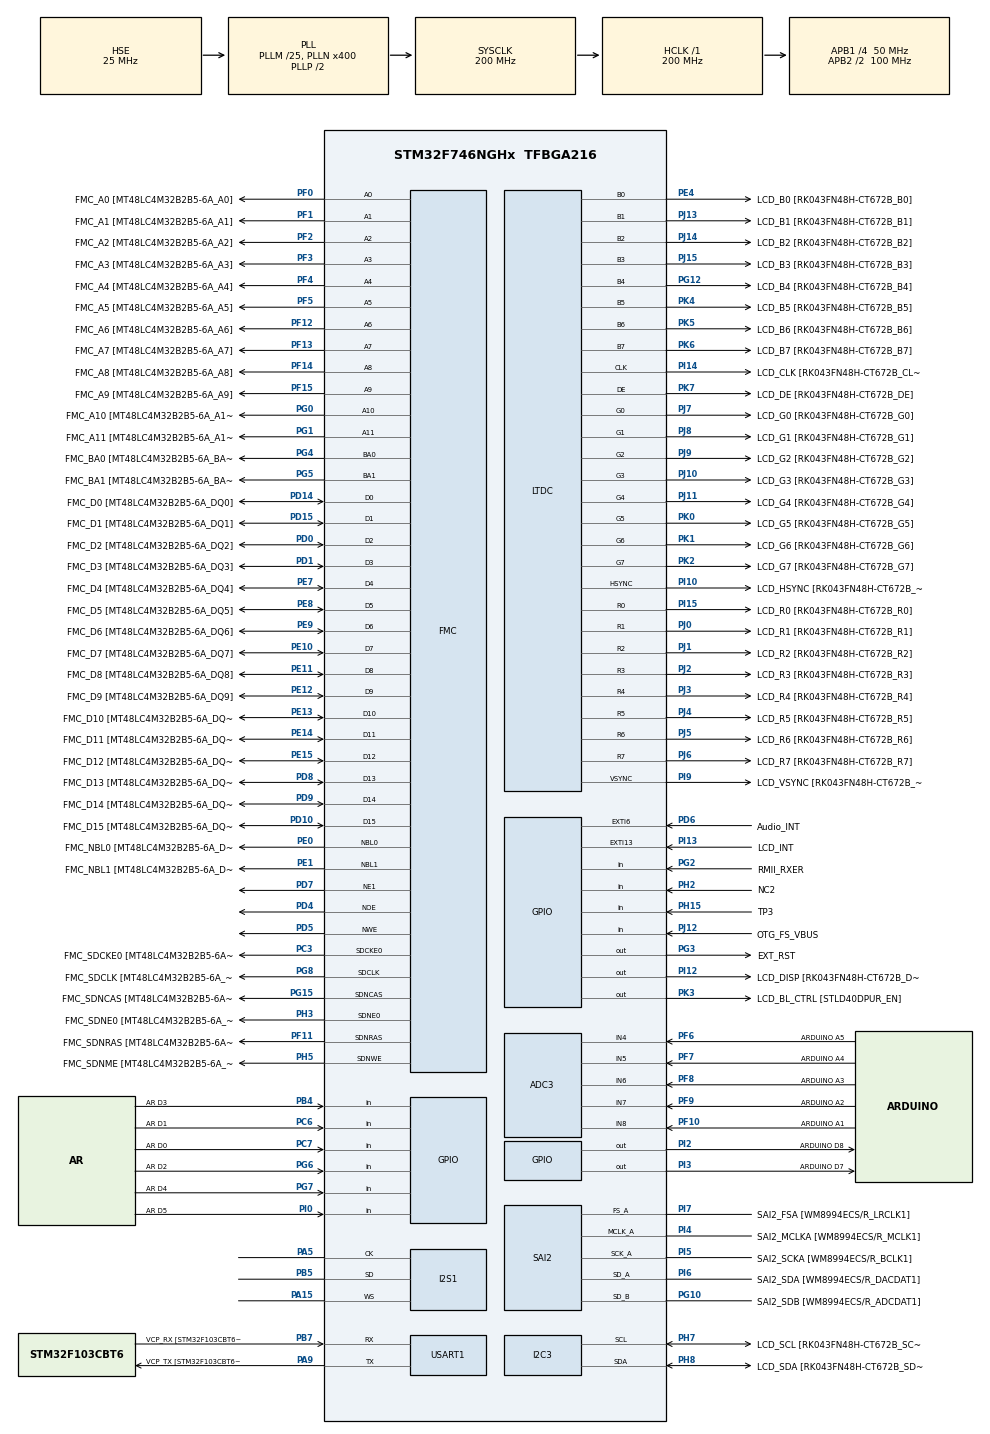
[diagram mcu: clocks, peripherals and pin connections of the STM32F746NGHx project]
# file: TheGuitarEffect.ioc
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ADC3.Channel-0\#ChannelRegularConversion=ADC_CHANNEL_4
ADC3.Channel-IN4=ADC_CHANNEL_4
ADC3.Channel-IN5=ADC_CHANNEL_5
ADC3.Channel-IN6=ADC_CHANNEL_6
ADC3.Channel-IN7=ADC_CHANNEL_7
ADC3.Channel-IN8=ADC_CHANNEL_8
ADC3.ContinuousConvMode=ENABLE
ADC3.EOCSelection=ADC_EOC_SEQ_CONV
CORTEX_M7.AccessPermission-Cortex_Memory_Protection_Unit_Region1_Settings=MPU_REGION_FULL_ACCESS
CORTEX_M7.AccessPermission-Cortex_Memory_Protection_Unit_Region2_Settings=MPU_REGION_FULL_ACCESS
CORTEX_M7.AccessPermission-Cortex_Memory_Protection_Unit_Region3_Settings=MPU_REGION_FULL_ACCESS
CORTEX_M7.BaseAddress-Cortex_Memory_Protection_Unit_Region0_Settings=0x00
CORTEX_M7.BaseAddress-Cortex_Memory_Protection_Unit_Region1_Settings=0xC0000000
CORTEX_M7.BaseAddress-Cortex_Memory_Protection_Unit_Region2_Settings=0x90000000
CORTEX_M7.BaseAddress-Cortex_Memory_Protection_Unit_Region3_Settings=0xA0000000
CORTEX_M7.CPU_DCache=Enabled
CORTEX_M7.CPU_ICache=Enabled
CORTEX_M7.DisableExec-Cortex_Memory_Protection_Unit_Region0_Settings=MPU_INSTRUCTION_ACCESS_DISABLE
CORTEX_M7.DisableExec-Cortex_Memory_Protection_Unit_Region3_Settings=MPU_INSTRUCTION_ACCESS_DISABLE
CORTEX_M7.Enable-Cortex_Memory_Protection_Unit_Region0_Settings=MPU_REGION_ENABLE
CORTEX_M7.Enable-Cortex_Memory_Protection_Unit_Region1_Settings=MPU_REGION_ENABLE
CORTEX_M7.Enable-Cortex_Memory_Protection_Unit_Region2_Settings=MPU_REGION_ENABLE
CORTEX_M7.Enable-Cortex_Memory_Protection_Unit_Region3_Settings=MPU_REGION_ENABLE
CORTEX_M7.IsBufferable-Cortex_Memory_Protection_Unit_Region3_Settings=MPU_ACCESS_BUFFERABLE
CORTEX_M7.IsCacheable-Cortex_Memory_Protection_Unit_Region1_Settings=MPU_ACCESS_CACHEABLE
CORTEX_M7.IsCacheable-Cortex_Memory_Protection_Unit_Region2_Settings=MPU_ACCESS_CACHEABLE
CORTEX_M7.IsShareable-Cortex_Memory_Protection_Unit_Region0_Settings=MPU_ACCESS_SHAREABLE
CORTEX_M7.IsShareable-Cortex_Memory_Protection_Unit_Region3_Settings=MPU_ACCESS_SHAREABLE
CORTEX_M7.MPU_Control=MPU_PRIVILEGED_DEFAULT
CORTEX_M7.Size-Cortex_Memory_Protection_Unit_Region0_Settings=MPU_REGION_SIZE_4GB
CORTEX_M7.Size-Cortex_Memory_Protection_Unit_Region1_Settings=MPU_REGION_SIZE_32MB
CORTEX_M7.Size-Cortex_Memory_Protection_Unit_Region2_Settings=MPU_REGION_SIZE_64MB
CORTEX_M7.Size-Cortex_Memory_Protection_Unit_Region3_Settings=MPU_REGION_SIZE_8KB
CORTEX_M7.SubRegionDisable-Cortex_Memory_Protection_Unit_Region0_Settings=0x87
CORTEX_M7.SubRegionDisable-Cortex_Memory_Protection_Unit_Region1_Settings=0x00
Dma.ADC3.0.Direction=DMA_PERIPH_TO_MEMORY
Dma.ADC3.0.FIFOMode=DMA_FIFOMODE_DISABLE
Dma.ADC3.0.Instance=DMA2_Stream1
Dma.ADC3.0.MemDataAlignment=DMA_MDATAALIGN_HALFWORD
Dma.ADC3.0.MemInc=DMA_MINC_ENABLE
Dma.ADC3.0.Mode=DMA_NORMAL
Dma.ADC3.0.PeriphDataAlignment=DMA_PDATAALIGN_HALFWORD
Dma.ADC3.0.PeriphInc=DMA_PINC_DISABLE
Dma.ADC3.0.Priority=DMA_PRIORITY_MEDIUM
Dma.Request0=ADC3
FMC.CASLatency1=FMC_SDRAM_CAS_LATENCY_3
FMC.ExitSelfRefreshDelay1=7
FMC.LoadToActiveDelay1=2
FMC.RCDDelay1=2
FMC.RPDelay1=2
FMC.ReadBurst1=FMC_SDRAM_RBURST_ENABLE
FMC.RowCycleDelay1=7
FMC.SDClockPeriod1=FMC_SDRAM_CLOCK_PERIOD_2
FMC.SelfRefreshTime1=4
FMC.WriteRecoveryTime1=3
I2C3.Timing=0x00C0EAFF
I2S1.ErrorAudioFreq=0.15 %
I2S1.FullDuplexMode=I2S_FULLDUPLEXMODE_DISABLE
I2S1.Instance=SPI$Index
I2S1.RealAudioFreq=8.012 KHz
I2S1.VirtualMode=I2S_MODE_MASTER
LTDC.ActiveH=272
LTDC.ActiveW=480
LTDC.Alpha_L0=255
LTDC.BlendingFactor1_L0=LTDC_BLENDING_FACTOR1_PAxCA
LTDC.BlendingFactor2_L0=LTDC_BLENDING_FACTOR2_PAxCA
LTDC.FBStartAdress_L0=0xC0000000
LTDC.HBP=13
LTDC.HFP=32
LTDC.HSync=41
LTDC.ImageHeight_L0=272
LTDC.ImageWidth_L0=480
LTDC.Layers=0
LTDC.PixelFormat_L0=LTDC_PIXEL_FORMAT_RGB565
LTDC.VSync=10
LTDC.WindowX1_L0=480
LTDC.WindowY1_L0=272
Mcu.Family=STM32F7
Mcu.Name=STM32F746NGHx
Mcu.Package=TFBGA216
NVIC.ADC_IRQn=true\:0\:0\:false\:false\:true\:true\:true\:true
NVIC.DMA2D_IRQn=true\:0\:0\:false\:false\:true\:true\:true\:true
NVIC.DMA2_Stream1_IRQn=true\:0\:0\:false\:false\:true\:false\:true\:true
NVIC.FMC_IRQn=true\:0\:0\:false\:false\:true\:true\:true\:true
NVIC.LTDC_IRQn=true\:0\:0\:false\:false\:true\:true\:true\:true
NVIC.PriorityGroup=NVIC_PRIORITYGROUP_4
NVIC.TIM6_DAC_IRQn=true\:15\:0\:false\:false\:true\:false\:true\:true
NVIC.TimeBase=TIM6_DAC_IRQn
NVIC.TimeBaseIP=TIM6
PA13.GPIO_Label=SWDIO
PA13.Mode=Serial_Wire
PA13.Signal=SYS_JTMS-SWDIO
PA14.GPIO_Label=SWCLK
PA14.Mode=Serial_Wire
PA14.Signal=SYS_JTCK-SWCLK
PA15.Mode=Half_Duplex_Master
PA15.Signal=I2S1_WS
PA5.Mode=Half_Duplex_Master
PA5.Signal=I2S1_CK
PA9.GPIO_Label=VCP_TX [STM32F103CBT6_PA3]
PA9.GPIO_Mode=GPIO_MODE_AF_PP
PA9.GPIO_PuPd=GPIO_NOPULL
PA9.GPIO_Speed=GPIO_SPEED_FREQ_LOW
PA9.Mode=Asynchronous
PA9.Signal=USART1_TX
PB3.GPIO_Label=SWO
PB3.Signal=SYS_JTDO-SWO
PB4.GPIO_Label=AR D3
PB4.Signal=GPIO_Input
PB5.Mode=Half_Duplex_Master
PB5.Signal=I2S1_SD
PB7.GPIO_Label=VCP_RX [STM32F103CBT6_PA2]
PB7.GPIO_Mode=GPIO_MODE_AF_PP
PB7.GPIO_PuPd=GPIO_NOPULL
PB7.GPIO_Speed=GPIO_SPEED_FREQ_LOW
PB7.Mode=Asynchronous
PB7.Signal=USART1_RX
PC14/OSC32_IN.GPIO_Label=RCC_OSC32_IN
PC14/OSC32_IN.Signal=RCC_OSC32_IN
PC15/OSC32_OUT.GPIO_Label=RCC_OSC32_OUT
PC15/OSC32_OUT.Signal=RCC_OSC32_OUT
PC3.GPIO_Label=FMC_SDCKE0 [MT48LC4M32B2B5-6A_CKE]
PC3.Mode=SdramChipSelect1_1
PC3.Signal=FMC_SDCKE0
PC6.GPIO_Label=AR D1
PC6.Signal=GPIO_Input
PC7.GPIO_Label=AR D0
PC7.Signal=GPIO_Input
PD0.GPIO_Label=FMC_D2 [MT48LC4M32B2B5-6A_DQ2]
PD0.Signal=FMC_D2_DA2
PD1.GPIO_Label=FMC_D3 [MT48LC4M32B2B5-6A_DQ3]
PD1.Signal=FMC_D3_DA3
PD10.GPIO_Label=FMC_D15 [MT48LC4M32B2B5-6A_DQ15]
PD10.Signal=FMC_D15_DA15
PD14.GPIO_Label=FMC_D0 [MT48LC4M32B2B5-6A_DQ0]
PD14.Signal=FMC_D0_DA0
PD15.GPIO_Label=FMC_D1 [MT48LC4M32B2B5-6A_DQ1]
PD15.Signal=FMC_D1_DA1
PD4.Signal=FMC_NOE
PD5.Signal=FMC_NWE
PD6.GPIO_Label=Audio_INT
PD6.GPIO_ModeDefaultEXTI=GPIO_MODE_EVT_RISING
PD6.Signal=GPXTI6
PD7.Mode=NorPsramChipSelect1_1
PD7.Signal=FMC_NE1
PD8.GPIO_Label=FMC_D13 [MT48LC4M32B2B5-6A_DQ13]
PD8.Signal=FMC_D13_DA13
PD9.GPIO_Label=FMC_D14 [MT48LC4M32B2B5-6A_DQ14]
PD9.Signal=FMC_D14_DA14
PE0.GPIO_Label=FMC_NBL0 [MT48LC4M32B2B5-6A_DQM0]
PE0.Signal=FMC_NBL0
PE1.GPIO_Label=FMC_NBL1 [MT48LC4M32B2B5-6A_DQM1]
PE1.Signal=FMC_NBL1
PE10.GPIO_Label=FMC_D7 [MT48LC4M32B2B5-6A_DQ7]
PE10.Signal=FMC_D7_DA7
PE11.GPIO_Label=FMC_D8 [MT48LC4M32B2B5-6A_DQ8]
PE11.Signal=FMC_D8_DA8
PE12.GPIO_Label=FMC_D9 [MT48LC4M32B2B5-6A_DQ9]
PE12.Signal=FMC_D9_DA9
PE13.GPIO_Label=FMC_D10 [MT48LC4M32B2B5-6A_DQ10]
PE13.Signal=FMC_D10_DA10
PE14.GPIO_Label=FMC_D11 [MT48LC4M32B2B5-6A_DQ11]
PE14.Signal=FMC_D11_DA11
PE15.GPIO_Label=FMC_D12 [MT48LC4M32B2B5-6A_DQ12]
PE15.Signal=FMC_D12_DA12
PE4.GPIO_Label=LCD_B0 [RK043FN48H-CT672B_B0]
PE4.Mode=RGB888
PE4.Signal=LTDC_B0
PE7.GPIO_Label=FMC_D4 [MT48LC4M32B2B5-6A_DQ4]
PE7.Signal=FMC_D4_DA4
PE8.GPIO_Label=FMC_D5 [MT48LC4M32B2B5-6A_DQ5]
PE8.Signal=FMC_D5_DA5
PE9.GPIO_Label=FMC_D6 [MT48LC4M32B2B5-6A_DQ6]
PE9.Signal=FMC_D6_DA6
PF0.GPIO_Label=FMC_A0 [MT48LC4M32B2B5-6A_A0]
PF0.Signal=FMC_A0
PF1.GPIO_Label=FMC_A1 [MT48LC4M32B2B5-6A_A1]
PF1.Signal=FMC_A1
PF10.GPIO_Label=ARDUINO A1
PF10.GPIO_Mode=GPIO_MODE_ANALOG
PF10.GPIO_PuPd=GPIO_NOPULL
PF10.Mode=IN8
PF10.Signal=ADC3_IN8
PF11.GPIO_Label=FMC_SDNRAS [MT48LC4M32B2B5-6A_RAS]
PF11.Signal=FMC_SDNRAS
PF12.GPIO_Label=FMC_A6 [MT48LC4M32B2B5-6A_A6]
PF12.Signal=FMC_A6
PF13.GPIO_Label=FMC_A7 [MT48LC4M32B2B5-6A_A7]
PF13.Signal=FMC_A7
PF14.GPIO_Label=FMC_A8 [MT48LC4M32B2B5-6A_A8]
PF14.Signal=FMC_A8
PF15.GPIO_Label=FMC_A9 [MT48LC4M32B2B5-6A_A9]
PF15.Signal=FMC_A9
PF2.GPIO_Label=FMC_A2 [MT48LC4M32B2B5-6A_A2]
PF2.Signal=FMC_A2
PF3.GPIO_Label=FMC_A3 [MT48LC4M32B2B5-6A_A3]
PF3.Signal=FMC_A3
PF4.GPIO_Label=FMC_A4 [MT48LC4M32B2B5-6A_A4]
PF4.Signal=FMC_A4
PF5.GPIO_Label=FMC_A5 [MT48LC4M32B2B5-6A_A5]
PF5.Signal=FMC_A5
PF6.GPIO_Label=ARDUINO A5
PF6.GPIO_Mode=GPIO_MODE_ANALOG
PF6.GPIO_PuPd=GPIO_NOPULL
PF6.Mode=IN4
PF6.Signal=ADC3_IN4
PF7.GPIO_Label=ARDUINO A4
PF7.GPIO_Mode=GPIO_MODE_ANALOG
PF7.GPIO_PuPd=GPIO_NOPULL
PF7.Mode=IN5
PF7.Signal=ADC3_IN5
PF8.GPIO_Label=ARDUINO A3
PF8.GPIO_Mode=GPIO_MODE_ANALOG
PF8.GPIO_PuPd=GPIO_NOPULL
PF8.Mode=IN6
PF8.Signal=ADC3_IN6
PF9.GPIO_Label=ARDUINO A2
PF9.GPIO_Mode=GPIO_MODE_ANALOG
PF9.GPIO_PuPd=GPIO_NOPULL
PF9.Mode=IN7
PF9.Signal=ADC3_IN7
PG0.GPIO_Label=FMC_A10 [MT48LC4M32B2B5-6A_A10]
PG0.Signal=FMC_A10
PG1.GPIO_Label=FMC_A11 [MT48LC4M32B2B5-6A_A11]
PG1.Signal=FMC_A11
PG10.GPIO_Label=SAI2_SDB [WM8994ECS/R_ADCDAT1]
PG10.GPIO_Speed=GPIO_SPEED_FREQ_MEDIUM
PG10.Mode=SAI_B_SyncSlave
PG10.Signal=SAI2_SD_B
PG12.GPIO_Label=LCD_B4 [RK043FN48H-CT672B_B4]
PG12.Mode=RGB888
PG12.Signal=LTDC_B4
PG15.GPIO_Label=FMC_SDNCAS [MT48LC4M32B2B5-6A_CAS]
PG15.Signal=FMC_SDNCAS
PG2.GPIO_Label=RMII_RXER
PG2.Signal=GPIO_Input
PG3.GPIO_Label=EXT_RST
PG3.Signal=GPIO_Output
PG4.GPIO_Label=FMC_BA0 [MT48LC4M32B2B5-6A_BA0]
PG4.Signal=FMC_A14_BA0
PG5.GPIO_Label=FMC_BA1 [MT48LC4M32B2B5-6A_BA1]
PG5.Signal=FMC_A15_BA1
PG6.GPIO_Label=AR D2
PG6.Signal=GPIO_Input
PG7.GPIO_Label=AR D4
PG7.Signal=GPIO_Input
PG8.GPIO_Label=FMC_SDCLK [MT48LC4M32B2B5-6A_CLK]
PG8.Signal=FMC_SDCLK
PH0/OSC_IN.GPIO_Label=OSC_25M [NZ2520SB-25.00M_OUT]
PH0/OSC_IN.Mode=HSE-External-Oscillator
PH0/OSC_IN.Signal=RCC_OSC_IN
PH1/OSC_OUT.Mode=HSE-External-Oscillator
PH1/OSC_OUT.Signal=RCC_OSC_OUT
PH15.GPIO_Label=TP3
PH15.Signal=GPIO_Input
PH2.GPIO_Label=NC2
PH2.Signal=GPIO_Input
PH3.GPIO_Label=FMC_SDNE0 [MT48LC4M32B2B5-6A_CS]
PH3.Mode=SdramChipSelect1_1
PH3.Signal=FMC_SDNE0
PH5.GPIO_Label=FMC_SDNME [MT48LC4M32B2B5-6A_WE]
PH5.Signal=FMC_SDNWE
PH7.GPIO_Label=LCD_SCL [RK043FN48H-CT672B_SCL]
PH7.GPIO_Pu=GPIO_PULLUP
PH7.Mode=I2C
PH7.Signal=I2C3_SCL
PH8.GPIO_Label=LCD_SDA [RK043FN48H-CT672B_SDA]
PH8.GPIO_Pu=GPIO_PULLUP
PH8.Mode=I2C
PH8.Signal=I2C3_SDA
PI0.GPIO_Label=AR D5
PI0.Signal=GPIO_Input
PI10.GPIO_Label=LCD_HSYNC [RK043FN48H-CT672B_HSYNC]
PI10.Mode=RGB888
PI10.Signal=LTDC_HSYNC
PI12.GPIO_Label=LCD_DISP [RK043FN48H-CT672B_DISP] 
PI12.PinState=GPIO_PIN_SET
PI12.Signal=GPIO_Output
PI13.GPIO_Label=LCD_INT
PI13.GPIO_ModeDefaultEXTI=GPIO_MODE_EVT_RISING
PI13.Signal=GPXTI13
PI14.GPIO_Label=LCD_CLK [RK043FN48H-CT672B_CLK]
PI14.Mode=RGB888
PI14.Signal=LTDC_CLK
PI15.GPIO_Label=LCD_R0 [RK043FN48H-CT672B_R0]
PI15.Mode=RGB888
PI15.Signal=LTDC_R0
PI2.GPIO_Label=ARDUINO D8
PI2.Signal=GPIO_Output
PI3.GPIO_Label=ARDUINO D7
PI3.Signal=GPIO_Output
PI4.GPIO_Label=SAI2_MCLKA [WM8994ECS/R_MCLK1]
PI4.GPIO_Speed=GPIO_SPEED_FREQ_MEDIUM
PI4.Mode=SAI_A_MasterWithClock
PI4.Signal=SAI2_MCLK_A
PI5.GPIO_Label=SAI2_SCKA [WM8994ECS/R_BCLK1]
PI5.GPIO_Speed=GPIO_SPEED_FREQ_MEDIUM
PI5.Mode=SAI_A_MasterWithClock
PI5.Signal=SAI2_SCK_A
PI6.GPIO_Label=SAI2_SDA [WM8994ECS/R_DACDAT1]
PI6.GPIO_Speed=GPIO_SPEED_FREQ_MEDIUM
PI6.Mode=SAI_A_MasterWithClock
PI6.Signal=SAI2_SD_A
PI7.GPIO_Label=SAI2_FSA [WM8994ECS/R_LRCLK1]
PI7.GPIO_Speed=GPIO_SPEED_FREQ_MEDIUM
PI7.Mode=SAI_A_MasterWithClock
PI7.Signal=SAI2_FS_A
PI8.GPIO_Label=NC1 [TP2]
PI8.Signal=RTC_TS
PI9.GPIO_Label=LCD_VSYNC [RK043FN48H-CT672B_VSYNC]
PI9.Mode=RGB888
PI9.Signal=LTDC_VSYNC
PJ0.GPIO_Label=LCD_R1 [RK043FN48H-CT672B_R1]
PJ0.Mode=RGB888
PJ0.Signal=LTDC_R1
PJ1.GPIO_Label=LCD_R2 [RK043FN48H-CT672B_R2]
PJ1.Mode=RGB888
PJ1.Signal=LTDC_R2
PJ10.GPIO_Label=LCD_G3 [RK043FN48H-CT672B_G3]
PJ10.Mode=RGB888
PJ10.Signal=LTDC_G3
PJ11.GPIO_Label=LCD_G4 [RK043FN48H-CT672B_G4]
PJ11.Mode=RGB888
PJ11.Signal=LTDC_G4
PJ12.GPIO_Label=OTG_FS_VBUS
PJ12.Signal=GPIO_Input
PJ13.GPIO_Label=LCD_B1 [RK043FN48H-CT672B_B1]
PJ13.Mode=RGB888
PJ13.Signal=LTDC_B1
PJ14.GPIO_Label=LCD_B2 [RK043FN48H-CT672B_B2]
PJ14.Mode=RGB888
PJ14.Signal=LTDC_B2
PJ15.GPIO_Label=LCD_B3 [RK043FN48H-CT672B_B3]
PJ15.Mode=RGB888
PJ15.Signal=LTDC_B3
PJ2.GPIO_Label=LCD_R3 [RK043FN48H-CT672B_R3]
PJ2.Mode=RGB888
PJ2.Signal=LTDC_R3
PJ3.GPIO_Label=LCD_R4 [RK043FN48H-CT672B_R4]
PJ3.Mode=RGB888
PJ3.Signal=LTDC_R4
PJ4.GPIO_Label=LCD_R5 [RK043FN48H-CT672B_R5]
PJ4.Mode=RGB888
PJ4.Signal=LTDC_R5
PJ5.GPIO_Label=LCD_R6 [RK043FN48H-CT672B_R6]
PJ5.Mode=RGB888
PJ5.Signal=LTDC_R6
PJ6.GPIO_Label=LCD_R7 [RK043FN48H-CT672B_R7]
PJ6.Mode=RGB888
PJ6.Signal=LTDC_R7
PJ7.GPIO_Label=LCD_G0 [RK043FN48H-CT672B_G0]
PJ7.Mode=RGB888
PJ7.Signal=LTDC_G0
PJ8.GPIO_Label=LCD_G1 [RK043FN48H-CT672B_G1]
PJ8.Mode=RGB888
PJ8.Signal=LTDC_G1
PJ9.GPIO_Label=LCD_G2 [RK043FN48H-CT672B_G2]
PJ9.Mode=RGB888
PJ9.Signal=LTDC_G2
PK0.GPIO_Label=LCD_G5 [RK043FN48H-CT672B_G5]
PK0.Mode=RGB888
PK0.Signal=LTDC_G5
PK1.GPIO_Label=LCD_G6 [RK043FN48H-CT672B_G6]
PK1.Mode=RGB888
PK1.Signal=LTDC_G6
PK2.GPIO_Label=LCD_G7 [RK043FN48H-CT672B_G7]
PK2.Mode=RGB888
PK2.Signal=LTDC_G7
PK3.GPIO_Label=LCD_BL_CTRL [STLD40DPUR_EN]
PK3.GPIO_Speed=GPIO_SPEED_FREQ_LOW
PK3.PinState=GPIO_PIN_SET
PK3.Signal=GPIO_Output
PK4.GPIO_Label=LCD_B5 [RK043FN48H-CT672B_B5]
PK4.Mode=RGB888
PK4.Signal=LTDC_B5
PK5.GPIO_Label=LCD_B6 [RK043FN48H-CT672B_B6]
PK5.Mode=RGB888
PK5.Signal=LTDC_B6
PK6.GPIO_Label=LCD_B7 [RK043FN48H-CT672B_B7]
PK6.Mode=RGB888
PK6.Signal=LTDC_B7
PK7.GPIO_Label=LCD_DE [RK043FN48H-CT672B_DE]
PK7.Mode=RGB888
PK7.Signal=LTDC_DE
ProjectManager.HeapSize=0x200
ProjectManager.StackSize=0x400
ProjectManager.TargetToolchain=STM32CubeIDE
RCC.AHBFreq_Value=200000000
RCC.APB1CLKDivider=RCC_HCLK_DIV4
RCC.APB1Freq_Value=50000000
RCC.APB1TimFreq_Value=100000000
RCC.APB2CLKDivider=RCC_HCLK_DIV2
RCC.APB2Freq_Value=100000000
RCC.APB2TimFreq_Value=200000000
RCC.CortexFreq_Value=200000000
RCC.HCLKFreq_Value=200000000
RCC.HSE_VALUE=25000000
RCC.HSI_VALUE=16000000
RCC.LSE_VALUE=32768
RCC.PLL48CLockSelection=RCC_CLK48SOURCE_PLLSAIP
RCC.PLLI2SN=100
RCC.PLLM=25
RCC.PLLN=400
RCC.PLLQ=9
RCC.PLLSAIN=384
RCC.PLLSAIP=RCC_PLLSAIP_DIV8
RCC.PLLSAIR=5
RCC.PLLSAIRDiv=RCC_PLLSAIDIVR_8
RCC.PLLSourceVirtual=RCC_PLLSOURCE_HSE
RCC.SDMMCClockSelection=RCC_SDMMC1CLKSOURCE_CLK48
RCC.SYSCLKFreq_VALUE=200000000
RCC.SYSCLKSource=RCC_SYSCLKSOURCE_PLLCLK
RCC.USBFreq_Value=48000000
RCC.VCOOutputFreq_Value=400000000
SAI2.ErrorAudioFreq-SAI_A_MasterWithClock=-2.34 %
SAI2.Instance-SAI_A_MasterWithClock=SAI$Index_Block_A
SAI2.Instance-SAI_B_SyncSlave=SAI$Index_Block_B
SAI2.MClockEnable-SAI_A_MasterWithClock=SAI_MASTERCLOCK_ENABLE
SAI2.RealAudioFreq-SAI_A_MasterWithClock=187.5 KHz
SAI2.Synchro-SAI_B_SyncSlave=SAI_SYNCHRONOUS
SAI2.VirtualMode-SAI_A_MasterWithClock=VM_MASTER
SAI2.VirtualMode-SAI_B_SyncSlave=VM_SLAVE
SH.FMC_A0.0=FMC_A0,12b-sda1
SH.FMC_A0.1=FMC_A0,12b-a1
SH.FMC_A1.0=FMC_A1,12b-sda1
SH.FMC_A1.1=FMC_A1,12b-a1
SH.FMC_A10.0=FMC_A10,12b-sda1
SH.FMC_A10.1=FMC_A10,12b-a1
SH.FMC_A11.0=FMC_A11,12b-sda1
SH.FMC_A11.1=FMC_A11,12b-a1
SH.FMC_A14_BA0.0=FMC_BA0,FourSdramBanks1
SH.FMC_A15_BA1.0=FMC_BA1,FourSdramBanks1
SH.FMC_A2.0=FMC_A2,12b-sda1
SH.FMC_A2.1=FMC_A2,12b-a1
SH.FMC_A3.0=FMC_A3,12b-sda1
SH.FMC_A3.1=FMC_A3,12b-a1
SH.FMC_A4.0=FMC_A4,12b-sda1
SH.FMC_A4.1=FMC_A4,12b-a1
SH.FMC_A5.0=FMC_A5,12b-sda1
SH.FMC_A5.1=FMC_A5,12b-a1
SH.FMC_A6.0=FMC_A6,12b-sda1
SH.FMC_A6.1=FMC_A6,12b-a1
SH.FMC_A7.0=FMC_A7,12b-sda1
SH.FMC_A7.1=FMC_A7,12b-a1
SH.FMC_A8.0=FMC_A8,12b-sda1
SH.FMC_A8.1=FMC_A8,12b-a1
SH.FMC_A9.0=FMC_A9,12b-sda1
SH.FMC_A9.1=FMC_A9,12b-a1
SH.FMC_D0_DA0.0=FMC_D0,sd-16b-d1
SH.FMC_D0_DA0.1=FMC_D0,16b-d1
SH.FMC_D10_DA10.0=FMC_D10,sd-16b-d1
SH.FMC_D10_DA10.1=FMC_D10,16b-d1
SH.FMC_D11_DA11.0=FMC_D11,sd-16b-d1
SH.FMC_D11_DA11.1=FMC_D11,16b-d1
SH.FMC_D12_DA12.0=FMC_D12,sd-16b-d1
SH.FMC_D12_DA12.1=FMC_D12,16b-d1
SH.FMC_D13_DA13.0=FMC_D13,sd-16b-d1
SH.FMC_D13_DA13.1=FMC_D13,16b-d1
SH.FMC_D14_DA14.0=FMC_D14,sd-16b-d1
SH.FMC_D14_DA14.1=FMC_D14,16b-d1
SH.FMC_D15_DA15.0=FMC_D15,sd-16b-d1
SH.FMC_D15_DA15.1=FMC_D15,16b-d1
SH.FMC_D1_DA1.0=FMC_D1,sd-16b-d1
SH.FMC_D1_DA1.1=FMC_D1,16b-d1
SH.FMC_D2_DA2.0=FMC_D2,sd-16b-d1
SH.FMC_D2_DA2.1=FMC_D2,16b-d1
SH.FMC_D3_DA3.0=FMC_D3,sd-16b-d1
SH.FMC_D3_DA3.1=FMC_D3,16b-d1
SH.FMC_D4_DA4.0=FMC_D4,sd-16b-d1
SH.FMC_D4_DA4.1=FMC_D4,16b-d1
SH.FMC_D5_DA5.0=FMC_D5,sd-16b-d1
SH.FMC_D5_DA5.1=FMC_D5,16b-d1
SH.FMC_D6_DA6.0=FMC_D6,sd-16b-d1
SH.FMC_D6_DA6.1=FMC_D6,16b-d1
SH.FMC_D7_DA7.0=FMC_D7,sd-16b-d1
SH.FMC_D7_DA7.1=FMC_D7,16b-d1
SH.FMC_D8_DA8.0=FMC_D8,sd-16b-d1
SH.FMC_D8_DA8.1=FMC_D8,16b-d1
SH.FMC_D9_DA9.0=FMC_D9,sd-16b-d1
SH.FMC_D9_DA9.1=FMC_D9,16b-d1
SH.FMC_NBL0.0=FMC_NBL0,Sd2ByteEnable1
SH.FMC_NBL1.0=FMC_NBL1,Sd2ByteEnable1
SH.FMC_NOE.0=FMC_NOE,Sram1
SH.FMC_NWE.0=FMC_NWE,Sram1
SH.FMC_SDCLK.0=FMC_SDCLK,12b-sda1
SH.FMC_SDNCAS.0=FMC_SDNCAS,12b-sda1
SH.FMC_SDNRAS.0=FMC_SDNRAS,12b-sda1
SH.FMC_SDNWE.0=FMC_SDNWE,12b-sda1
USART1.VirtualMode-Asynchronous=VM_ASYNC
VP_DMA2D_VS_DMA2D.Mode=DMA2D_Activate
VP_SYS_VS_tim6.Mode=TIM6
VP_TIM2_VS_ClockSourceINT.Mode=Internal
board=STM32F746G-DISCO

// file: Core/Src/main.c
#include "main.h"
#include "adc.h"
#include "dma.h"
#include "dma2d.h"
#include "i2c.h"
#include "i2s.h"
#include "ltdc.h"
#include "sai.h"
#include "tim.h"
#include "usart.h"
#include "gpio.h"
#include "fmc.h"

/* USER CODE BEGIN Includes */
#include "stm32f7xx_hal_adc.h"
#include "string.h"
#include <math.h>
/* USER CODE END Includes */

/* USER CODE BEGIN PD */
#define LCD_COLOR_RUBYRED		((uint32_t)0xFFB22222)
/* USER CODE END PD */

/* USER CODE BEGIN PV */
int EffectIndex = 0;
int ParameterIndex = 0;

/* USER CODE END PV */

void SystemClock_Config(void);
void PeriphCommonClock_Config(void);
static void MPU_Config(void);

/* USER CODE BEGIN 0 */

uint8_t CheckForUserInput() {
    if (BSP_PB_GetState(BUTTON_KEY) != RESET) {
        HAL_Delay(10);

        while (BSP_PB_GetState(BUTTON_KEY) != RESET);

        return 1 ;
    }
    return 0;
}

extern EffectTypedef effects[] = {
    {"DISTORTION", 2, 0.0, 0.0, 0.0, 0.0}, 	// ?"           ", 1"Gain", 2"Threshold", ?"    ", ?"        ", ?"   ", ?"           "
    {"FUZZ", 3, 0.0, 0.0, 0.0, 0.0}, 		// 1"Depth      ", 3"Gain", 2"Threshold", ?"    ", ?"        ", ?"   ", ?"           "
    {"FLANGER", 4, 0.0, 0.0, 0.0, 0.0}, 		// 1"Delay-Depth", ?"    ", ?"         ", 2"Rate", 3"Feedback", 4"Mix", ?"           "
    {"ROTARY", 2, 0.0, 0.0, 0.0, 0.0},		// 1"Depth      ", ?"    ", ?"         ", 2"Rate", ?"        ", ?"   ", ?"           "
    {"REVERB", 2, 0.0, 0.0, 0.0, 0.0},		// ?"           ", ?"    ", ?"         ", ?"    ", ?"        ", 2"Mix", 1"Reverb-Time"
    {"DELAY", 3, 0.0, 0.0, 0.0, 0.0}, 		// 1"Delay-Depth", ?"    ", ?"         ", ?"    ", 3"Feedback", 2"Mix", ?"         "
};

// just set it as global, don't pass in. It doesn't matter
char effect_names[6][4][15] = {
    {"Gain", "Threshold"},
    {"Depth", "Threshold", "Gain"},
    {"Delay-Depth", "Rate", "Feedback", "Mix"},
    {"Depth", "Rate"},
    {"Reverb-Time", "Mix"},
    {"Delay-Depth", "Mix", "Feedback"}
};

//float depthMax[6] = {0.0, 2.4, 6.0, 1.6, 0.0, 900.0};
//float gainMax[6] = {2.4, 3.0, 0.0, 0.0, 0.0, 0.0};
//float thresholdMax[6] = {50000, 30000, 0.0, 0.0, 0.0, 0.0};
//float rateMax[6] = {0.0, 0.0, 1.0, 8.0, 0.0, 0.0};
//float feedbackMax[6] = {0.0, 0.0, 0.6, 0.0, 0.0, 0.8};
//float mixMax[6] = {0.0, 0.0, 1.2, 0.0, 1.4, 1.2};
//float reverbTimeMax[6] = {0.0, 0.0, 0.0, 0.0, 1000.0, 0.0};

// display code
// min = 0, max = 4096 -> find percentage -> put in the middle
// try drawing many circles on top of each other
// radius should be static
static void Effect_Circle_Display(uint16_t center_x, uint16_t center_y, uint8_t percentage, char* val_name, uint8_t isActive);
static void Display_Detail(char* mode_name, char* state_name);
static int average_8(float x);
static int average_16(float x);
static uint8_t convertToPercentage(int x);
//static void update_percentage_display(uint16_t center_x, uint16_t center_y, uint8_t percentage, uint8_t isActive);
static void update_guage_value(uint16_t center_x, uint16_t center_y, uint8_t start, uint8_t stop, uint8_t percentage, uint8_t isActive);

// extern function for button interrupts
extern void change_effect_display();
extern void change_guage_display(uint8_t isActive);
extern void update_guage_value_display();

//uint8_t prev_percentage = 0;
//uint8_t can_update_parameter = 1;
//uint8_t ext_intrpt_enable = 1;
uint8_t prevADCValue = 0;

/* USER CODE END 0 */

int main(void)
{

  /* MPU Configuration--------------------------------------------------------*/
  MPU_Config();

  /* Enable the CPU Cache */

  /* Enable I-Cache---------------------------------------------------------*/
  SCB_EnableICache();

  /* Enable D-Cache---------------------------------------------------------*/
  SCB_EnableDCache();

  /* MCU Configuration--------------------------------------------------------*/

  /* Reset of all peripherals, Initializes the Flash interface and the Systick. */
  HAL_Init();

  /* Configure the system clock */
  SystemClock_Config();

  /* Configure the peripherals common clocks */
  PeriphCommonClock_Config();

  /* Initialize all configured peripherals */
  MX_GPIO_Init();
  MX_DMA_Init();
  MX_ADC3_Init();
  MX_DMA2D_Init();
  MX_FMC_Init();
  MX_I2C3_Init();
  MX_LTDC_Init();
  MX_SAI2_Init();
  MX_TIM2_Init();
  MX_USART1_UART_Init();
  MX_I2S1_Init();
  /* USER CODE BEGIN 2 */

  // HAL_ADC_Start_DMA(&hadc3, );

	BSP_LED_Init(LED1);
	BSP_PB_Init(BUTTON_KEY, BUTTON_MODE_GPIO);
	BSP_LCD_Init();
	BSP_LCD_LayerDefaultInit(LTDC_ACTIVE_LAYER, LCD_FRAME_BUFFER);

  /* USER CODE END 2 */
  /* Infinite loop */
  /* USER CODE BEGIN WHILE */

  // change_effect_display();
  // change_guage_display(1);

	BSP_LCD_SelectLayer(LTDC_ACTIVE_LAYER);
	BSP_LCD_SetBackColor(LCD_COLOR_WHITE);
  BSP_LCD_Clear(LCD_COLOR_WHITE);

	BSP_LCD_SetFont(&Font16);
	BSP_LCD_SetTextColor(LCD_COLOR_BLUE);
	BSP_LCD_FillRect(0, BSP_LCD_GetYSize() / 2 + 15, BSP_LCD_GetXSize(), 60);
	BSP_LCD_SetTextColor(LCD_COLOR_WHITE);
	BSP_LCD_SetBackColor(LCD_COLOR_BLUE);
	BSP_LCD_DisplayStringAt(0, BSP_LCD_GetYSize() / 2 + 30, (uint8_t *)"Press User Button to start :", CENTER_MODE);
	BSP_LCD_DisplayStringAt(0, BSP_LCD_GetYSize() / 2 + 45, (uint8_t *)"AUDIO RECORD example", CENTER_MODE);

  while (1) {
    /* USER CODE END WHILE */
    /* USER CODE BEGIN 3 */

	  if (BSP_PB_GetState(BUTTON_KEY) != RESET) {
        HAL_Delay(10);
        while (BSP_PB_GetState(BUTTON_KEY) != RESET);

        // set to inactive all
        change_guage_ddisplay(0);

        // disable all interrupts
  //      __disable_irq();

        // change to disable just exti15 and exti0
        HAL_NVIC_DisableIRQ(EXTI0_IRQn);

        // this line doesn't seem to work at all
        HAL_NVIC_DisableIRQ(EXTI15_10_IRQn);

        AudioRec_demo();

        // so this is quite easy
        // we want to update the thing according to parameter index
        // we check which parameter index it is
        // we check if the value is
        // current adjustable value
        uint8_t prev_percentage = 0;
        int adc_read = average_8(uhADCxConvertedValue);

        switch (ParameterIndex) {
            case 0:
                prev_percentage = convertToPercentage(effects[EffectIndex].Parameter1);
                effects[EffectIndex].Parameter1 = adc_read;
                break;
            case 1:
                prev_percentage = convertToPercentage(effects[EffectIndex].Parameter2);
                effects[EffectIndex].Parameter2 = adc_read;
                break;
            case 2:
                prev_percentage = convertToPercentage(effects[EffectIndex].Parameter3);
                effects[EffectIndex].Parameter3 = adc_read;
                break;
            case 3:
                prev_percentage = convertToPercentage(effects[EffectIndex].Parameter4);
                effects[EffectIndex].Parameter4 = adc_read;
                break;
            default:
                break;
        }

        // update data
        uint8_t cur_percentage = convertToPercentage(adc_read);

        if (cur_percentage != prev_percentage) {
            update_guage_value_display();
            prev_percentage = cur_percentage;
        }
        HAL_Delay(10);
     }
  }
  /* USER CODE END 3 */
}

void SystemClock_Config(void)
{
  RCC_OscInitTypeDef RCC_OscInitStruct = {0};
  RCC_ClkInitTypeDef RCC_ClkInitStruct = {0};

  /** Configure the main internal regulator output voltage
  */
  __HAL_RCC_PWR_CLK_ENABLE();
  __HAL_PWR_VOLTAGESCALING_CONFIG(PWR_REGULATOR_VOLTAGE_SCALE1);

  /** Initializes the RCC Oscillators according to the specified parameters
  * in the RCC_OscInitTypeDef structure.
  */
  RCC_OscInitStruct.OscillatorType = RCC_OSCILLATORTYPE_HSE;
  RCC_OscInitStruct.HSEState = RCC_HSE_ON;
  RCC_OscInitStruct.PLL.PLLState = RCC_PLL_ON;
  RCC_OscInitStruct.PLL.PLLSource = RCC_PLLSOURCE_HSE;
  RCC_OscInitStruct.PLL.PLLM = 25;
  RCC_OscInitStruct.PLL.PLLN = 400;
  RCC_OscInitStruct.PLL.PLLP = RCC_PLLP_DIV2;
  RCC_OscInitStruct.PLL.PLLQ = 9;
  if (HAL_RCC_OscConfig(&RCC_OscInitStruct) != HAL_OK)
  {
    Error_Handler();
  }

  /** Activate the Over-Drive mode
  */
  if (HAL_PWREx_EnableOverDrive() != HAL_OK)
  {
    Error_Handler();
  }

  /** Initializes the CPU, AHB and APB buses clocks
  */
  RCC_ClkInitStruct.ClockType = RCC_CLOCKTYPE_HCLK|RCC_CLOCKTYPE_SYSCLK
                              |RCC_CLOCKTYPE_PCLK1|RCC_CLOCKTYPE_PCLK2;
  RCC_ClkInitStruct.SYSCLKSource = RCC_SYSCLKSOURCE_PLLCLK;
  RCC_ClkInitStruct.AHBCLKDivider = RCC_SYSCLK_DIV1;
  RCC_ClkInitStruct.APB1CLKDivider = RCC_HCLK_DIV4;
  RCC_ClkInitStruct.APB2CLKDivider = RCC_HCLK_DIV2;

  if (HAL_RCC_ClockConfig(&RCC_ClkInitStruct, FLASH_LATENCY_6) != HAL_OK)
  {
    Error_Handler();
  }
}

void PeriphCommonClock_Config(void)
{
  RCC_PeriphCLKInitTypeDef PeriphClkInitStruct = {0};

  /** Initializes the peripherals clock
  */
  PeriphClkInitStruct.PeriphClockSelection = RCC_PERIPHCLK_LTDC|RCC_PERIPHCLK_SAI2;
  PeriphClkInitStruct.PLLSAI.PLLSAIN = 384;
  PeriphClkInitStruct.PLLSAI.PLLSAIR = 5;
  PeriphClkInitStruct.PLLSAI.PLLSAIQ = 2;
  PeriphClkInitStruct.PLLSAI.PLLSAIP = RCC_PLLSAIP_DIV8;
  PeriphClkInitStruct.PLLSAIDivQ = 1;
  PeriphClkInitStruct.PLLSAIDivR = RCC_PLLSAIDIVR_8;
  PeriphClkInitStruct.Sai2ClockSelection = RCC_SAI2CLKSOURCE_PLLSAI;
  if (HAL_RCCEx_PeriphCLKConfig(&PeriphClkInitStruct) != HAL_OK)
  {
    Error_Handler();
  }
}

/* USER CODE BEGIN 4 */

void HAL_GPIO_EXTI_Callback(uint16_t GPIO_Pin) {
  static uint32_t debounce_time = 0;

  if (GPIO_Pin == KEY_BUTTON_PIN) {
    /* Prevent debounce effect for user key */
    if ((HAL_GetTick() - debounce_time) > 50) {
      debounce_time = HAL_GetTick();
    }
  }
  else if (GPIO_Pin == AUDIO_IN_INT_GPIO_PIN) {
    /* Audio IN interrupt */
  }
}

void HAL_ADC_ConvCpltCallback(ADC_HandleTypeDef* AdcHandle) {
  /* Turn LED1 on: Transfer process is correct */
	BSP_LED_Toggle(LED1);
	HAL_Delay(1000);
}

/* USER CODE END 4 */

 /* MPU Configuration */

void MPU_Config(void)
{
  MPU_Region_InitTypeDef MPU_InitStruct = {0};

  /* Disables the MPU */
  HAL_MPU_Disable();

  /** Initializes and configures the Region and the memory to be protected
  */
  MPU_InitStruct.Enable = MPU_REGION_ENABLE;
  MPU_InitStruct.Number = MPU_REGION_NUMBER0;
  MPU_InitStruct.BaseAddress = 0x00;
  MPU_InitStruct.Size = MPU_REGION_SIZE_4GB;
  MPU_InitStruct.SubRegionDisable = 0x87;
  MPU_InitStruct.TypeExtField = MPU_TEX_LEVEL0;
  MPU_InitStruct.AccessPermission = MPU_REGION_NO_ACCESS;
  MPU_InitStruct.DisableExec = MPU_INSTRUCTION_ACCESS_DISABLE;
  MPU_InitStruct.IsShareable = MPU_ACCESS_SHAREABLE;
  MPU_InitStruct.IsCacheable = MPU_ACCESS_NOT_CACHEABLE;
  MPU_InitStruct.IsBufferable = MPU_ACCESS_NOT_BUFFERABLE;

  HAL_MPU_ConfigRegion(&MPU_InitStruct);

  /** Initializes and configures the Region and the memory to be protected
  */
  MPU_InitStruct.Number = MPU_REGION_NUMBER1;
  MPU_InitStruct.BaseAddress = 0xC0000000;
  MPU_InitStruct.Size = MPU_REGION_SIZE_32MB;
  MPU_InitStruct.SubRegionDisable = 0x00;
  MPU_InitStruct.AccessPermission = MPU_REGION_FULL_ACCESS;
  MPU_InitStruct.DisableExec = MPU_INSTRUCTION_ACCESS_ENABLE;
  MPU_InitStruct.IsShareable = MPU_ACCESS_NOT_SHAREABLE;
  MPU_InitStruct.IsCacheable = MPU_ACCESS_CACHEABLE;

  HAL_MPU_ConfigRegion(&MPU_InitStruct);

  /** Initializes and configures the Region and the memory to be protected
  */
  MPU_InitStruct.Number = MPU_REGION_NUMBER2;
  MPU_InitStruct.BaseAddress = 0x90000000;
  MPU_InitStruct.Size = MPU_REGION_SIZE_64MB;
  MPU_InitStruct.SubRegionDisable = 0x0;

  HAL_MPU_ConfigRegion(&MPU_InitStruct);

  /** Initializes and configures the Region and the memory to be protected
  */
  MPU_InitStruct.Number = MPU_REGION_NUMBER3;
  MPU_InitStruct.BaseAddress = 0xA0000000;
  MPU_InitStruct.Size = MPU_REGION_SIZE_8KB;
  MPU_InitStruct.DisableExec = MPU_INSTRUCTION_ACCESS_DISABLE;
  MPU_InitStruct.IsShareable = MPU_ACCESS_SHAREABLE;
  MPU_InitStruct.IsCacheable = MPU_ACCESS_NOT_CACHEABLE;
  MPU_InitStruct.IsBufferable = MPU_ACCESS_BUFFERABLE;

  HAL_MPU_ConfigRegion(&MPU_InitStruct);
  /* Enables the MPU */
  HAL_MPU_Enable(MPU_PRIVILEGED_DEFAULT);

}

void HAL_TIM_PeriodElapsedCallback(TIM_HandleTypeDef *htim)
{
  if (htim->Instance == TIM6) {
    HAL_IncTick();
  }
}

void Error_Handler(void)
{
  __disable_irq();
  while (1)
  {
  }
}
